# USB1_DEBUG_TRACE_MMR_TRACE_VBUSP_USB2SS_DEBUG_TRACE register map
Vendor: Texas Instruments
Peripheral module from a debugger description file (folder am62P).
Registers are 32-bit, access per field, reset 0x0 unless marked. A register's access mark holds for its fields unless they carry their own. Offsets are as the file gives them; lines under a group give offsets from that group; [hi:lo] are bit positions; {n}, {i} and the like mark numbered series; 'fields as' and 'values as' point back to an identical list; <NAME> marks a mode.

## USB1_DEBUG_TRACE_MMR_TRACE_VBUSP_USB2SS_DEBUG_TRACE
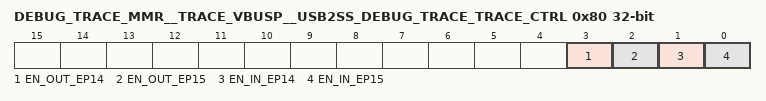
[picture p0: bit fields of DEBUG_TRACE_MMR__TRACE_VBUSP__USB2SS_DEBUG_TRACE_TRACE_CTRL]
0x80 DEBUG_TRACE_MMR__TRACE_VBUSP__USB2SS_DEBUG_TRACE_TRACE_CTRL — Debug trace control register
  [3] EN_OUT_EP14 rw — Debug trace enable for OUT Endpoint 14
  [2] EN_OUT_EP15 rw — Debug trace enable for OUT Endpoint 15
  [1] EN_IN_EP14 rw — Debug trace enable for IN Endpoint 14
  [0] EN_IN_EP15 rw — Debug trace enable for IN Endpoint 15
